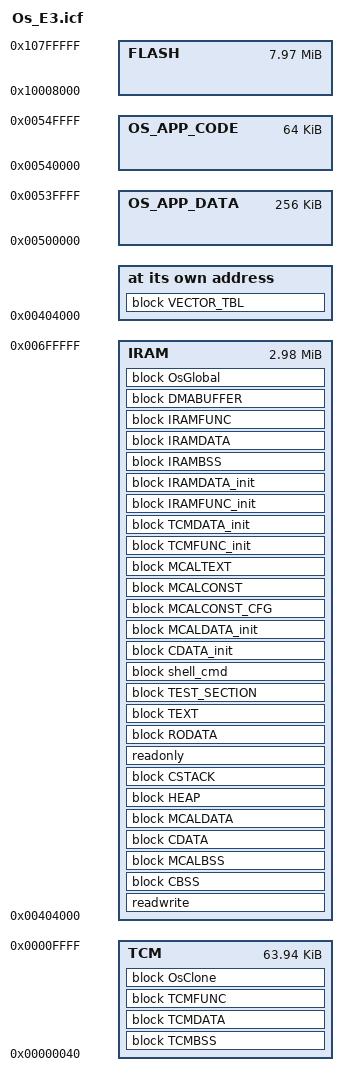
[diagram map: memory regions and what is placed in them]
/*============================================================================*/
/*  Copyright (C) iSOFT   (2022), iSOFT INFRASTRUCTURE SOFTWARE CO.,LTD.
 *  
 *  All rights reserved. This software is iSOFT property. Duplication 
 *  or disclosure without iSOFT written authorization is prohibited.
 *  
 *  @file       <Os_E3.icf>
 *  @brief      <>
 *  
 *  <MCU:E3420>
 *  
 *  @author     <>
 *  @date       <2023-10-24 18:03:15>
 */
/*============================================================================*/

define symbol intvec_start__ = 0x404000;

define symbol STACK_SZ = 0x14000;
define symbol HEAP_SZ = 0x4000;
define symbol DMA_BLOCK_SZ = 0x10000;

define memory mem with size = 4G;

define region TCM = mem:[from 0x40 to 0xffff];
define region FLASH = mem:[from 0x10008000 to 0x107fffff];
define region IRAM = mem:[from 0x404000 to 0x6fffff];

do not initialize  { section .noinit };
do not initialize  { section .zeroinit };
do not initialize  { section .bss };
do not initialize  { section .iram_bss };
do not initialize  { section .tcm_bss };
do not initialize  { section .mcal_bss.* };
do not initialize  { section .dma_buffer };
initialize manually { readwrite };
initialize manually { section .data};
initialize manually { section .mcal_data.* };
initialize manually { section .iram_data };
initialize manually { section .tcm_data };
initialize manually { section .tcm_func, section .mcal_text.fast.* };
initialize manually { section .iram_func };

define block VECTOR_TBL with alignment = 32        { readonly section .vector };

define block TEST_SECTION    with alignment = 32    { readonly section TEST_SECTION};
define block shell_cmd       with alignment = 32    { readonly section shell_cmd};

define block CBSS            with alignment = 32   { section .bss};
define block MCALBSS         with alignment = 32   { section .mcal_bss.* };
define block CDATA           with alignment = 32   { section .data };
define block MCALDATA        with alignment = 32   { section .mcal_data.* };
define block MCALCONST_CFG   with alignment = 32   { readonly section .mcal_const_cfg.* };
define block MCALCONST       with alignment = 32   { readonly section .mcal_const.* };
define block MCALTEXT        with alignment = 32   { section .mcal_text.* };
define block IRAMFUNC        with alignment = 32   { section .iram_func };
define block TCMFUNC         with alignment = 32   { section .tcm_func, section .mcal_text.fast.* };
define block IRAMDATA        with alignment = 32   { section .iram_data };
define block TCMDATA         with alignment = 32   { section .tcm_data };
define block IRAMBSS         with alignment = 32   { section .iram_bss };
define block TCMBSS          with alignment = 32   { section .tcm_bss};
define block TEXT            with alignment = 32   { section .text};
define block RODATA          with alignment = 32   { section .rodata};

define block CDATA_init      with alignment = 32   { section .data_init };
define block MCALDATA_init   with alignment = 32   { section .mcal_data.*_init };
define block IRAMFUNC_init   with alignment = 32   { section .iram_func_init };
define block TCMFUNC_init    with alignment = 32   { section .tcm_func_init, section .mcal_text.fast.*_init };
define block IRAMDATA_init   with alignment = 32   { section .iram_data_init };
define block TCMDATA_init    with alignment = 32   { section .tcm_data_init };

define block DMABUFFER       with alignment = 64k, size       = DMA_BLOCK_SZ { readwrite section .dma_buffer };

define block CSTACK          with alignment = 32, size         = STACK_SZ     { };
define block HEAP            with alignment = 32, minimum size = HEAP_SZ, expanding size { };

place in IRAM  { readwrite };
place in IRAM  { block CBSS };
place in IRAM  { block MCALBSS };
place in IRAM  { block CDATA };
place in IRAM  { block MCALDATA };
place in IRAM  { block HEAP, block CSTACK };

place in TCM   { block TCMBSS };
place in TCM   { block TCMDATA };
place in TCM   { block TCMFUNC };

place in IRAM  { readonly, block RODATA, block TEXT, block TEST_SECTION, block shell_cmd};
place in IRAM  { block CDATA_init };
place in IRAM  { block MCALDATA_init };
place in IRAM  { block MCALCONST_CFG };
place in IRAM  { block MCALCONST };
place in IRAM  { block MCALTEXT };
place in IRAM  { block TCMFUNC_init };
place in IRAM  { block TCMDATA_init };
place in IRAM  { block IRAMFUNC_init };
place in IRAM  { block IRAMDATA_init };

place in IRAM { block IRAMBSS };
place in IRAM { block IRAMDATA };
place in IRAM { block IRAMFUNC };
place in IRAM { block DMABUFFER};

place at address mem:intvec_start__ { block VECTOR_TBL };

export symbol intvec_start__;



//==================================================================
// the symbol below is modified by os.
//==================================================================
define symbol app_ram_start__ = 0x500000;
define symbol app_ram_end__   = 0x53ffff;
define symbol app_rom_start__ = 0x540000;
define symbol app_rom_end__   = 0x54ffff;

export symbol app_ram_start__;
export symbol app_ram_end__;
export symbol app_rom_start__;
export symbol app_rom_end__;

define region OS_APP_DATA = mem:[from app_ram_start__ to app_ram_end__];
define region OS_APP_CODE = mem:[from app_rom_start__ to app_rom_end__];

do not initialize  { section .BswDataShared };
do not initialize  { section .os_global };

define block OsClone       with alignment = 32   { section .BswDataShared };
define block OsGlobal      with alignment = 4k,  size = 4k { section .os_global };

place in TCM   { block OsClone };
place in IRAM  { block OsGlobal };

	



